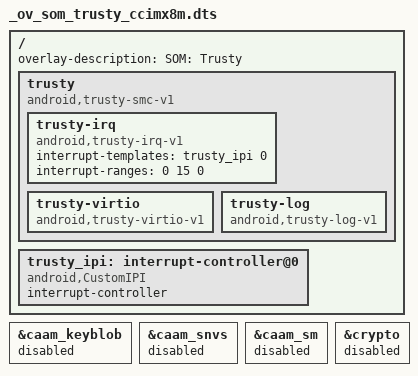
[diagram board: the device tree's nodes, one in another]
/*
 * Copyright 2021 Digi International Inc.
 *
 * Permission to use, copy, modify, and/or distribute this software for any
 * purpose with or without fee is hereby granted, provided that the above
 * copyright notice and this permission notice appear in all copies.
 * THE SOFTWARE IS PROVIDED "AS IS" AND THE AUTHOR DISCLAIMS ALL WARRANTIES
 * WITH REGARD TO THIS SOFTWARE INCLUDING ALL IMPLIED WARRANTIES OF
 * MERCHANTABILITY AND FITNESS. IN NO EVENT SHALL THE AUTHOR BE LIABLE FOR
 * ANY SPECIAL, DIRECT, INDIRECT, OR CONSEQUENTIAL DAMAGES OR ANY DAMAGES
 * WHATSOEVER RESULTING FROM LOSS OF USE, DATA OR PROFITS, WHETHER IN AN
 * ACTION OF CONTRACT, NEGLIGENCE OR OTHER TORTIOUS ACTION, ARISING OUT OF
 * OR IN CONNECTION WITH THE USE OR PERFORMANCE OF THIS SOFTWARE.
 */

/dts-v1/;
/plugin/;

/ {
	fragment@0 {
		target-path = "/";
		__overlay__ {
			overlay-description = "SOM: Trusty";
		};
	};

	fragment@1 {
		target-path = "/";
		__overlay__ {
			trusty {
				compatible = "android,trusty-smc-v1";
				ranges;
				#address-cells = <2>;
				#size-cells = <2>;
				trusty-irq {
					compatible = "android,trusty-irq-v1";
					interrupt-templates = <&trusty_ipi 0>;
					interrupt-ranges = < 0 15 0>;
				};
				trusty-virtio {
					compatible = "android,trusty-virtio-v1";
				};
				trusty-log {
					compatible = "android,trusty-log-v1";
				};
			};
			trusty_ipi: interrupt-controller@0 {
				compatible = "android,CustomIPI";
				interrupt-controller;
				#interrupt-cells = <1>;
			};
		};
	};

	/* Disable CAAM */
	fragment@2 {
		target = <&caam_keyblob>;
		__overlay__ {
			status = "disabled";
		};
	};

	fragment@3 {
		target = <&caam_snvs>;
		__overlay__ {
			status = "disabled";
		};
	};

	fragment@4 {
		target = <&caam_sm>;
		__overlay__ {
			status = "disabled";
		};
	};

	fragment@5 {
		target = <&crypto>;
		__overlay__ {
			status = "disabled";
		};
	};
};
